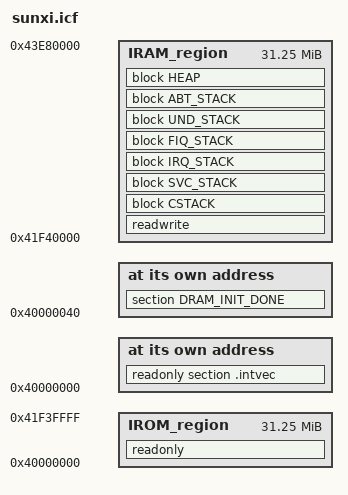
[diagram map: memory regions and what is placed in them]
/*###ICF### Section handled by ICF editor, don't touch! ****/
/*-Editor annotation file-*/
/* IcfEditorFile="$TOOLKIT_DIR$\config\ide\IcfEditor\a_v1_1.xml" */
/*-Specials-*/
if (isdefinedsymbol(DDR))
{
  /* 32Mb code */
  define symbol __ICFEDIT_region_IROM1_start__ = 0x40000000;
  define symbol __ICFEDIT_region_IROM1_end__   = 0x41F3FFFF;
  /* 32Mb data */
  define symbol __ICFEDIT_region_IRAM1_start__ = 0x41F40000;
  define symbol __ICFEDIT_region_IRAM1_end__   = 0x43E80000;
}
else 
{
  if (isdefinedsymbol(SOC_ID))
  {
    if (SOC_ID == 5)
    
    {
      /* 32Kb ROM */
      define symbol __ICFEDIT_region_IROM1_start__ = 0x00010000;
      define symbol __ICFEDIT_region_IROM1_end__   = 0x00017FFF;
      /* 112Kb RAM */
      define symbol __ICFEDIT_region_IRAM1_start__ = 0x00018000;
      define symbol __ICFEDIT_region_IRAM1_end__   = 0x00033FFF;
    }
    else if (SOC_ID == 616 || SOC_ID == 6)
    {
      /* 36Kb ROM */
      define symbol __ICFEDIT_region_IROM1_start__ = 0x00020000;
      define symbol __ICFEDIT_region_IROM1_end__   = 0x00028FFF;
      /* 192Kb RAM */
      define symbol __ICFEDIT_region_IRAM1_start__ = 0x00029000;
      define symbol __ICFEDIT_region_IRAM1_end__   = 0x00057FFF;  
    }
  }
  else /* V3s, H3, R40 SRAM */
  {
    /* 28Kb ROM */
    define symbol __ICFEDIT_region_IROM1_start__ = 0x00000000;
    define symbol __ICFEDIT_region_IROM1_end__   = 0x00006FFF;
    /* 20Kb RAM */
    define symbol __ICFEDIT_region_IRAM1_start__ = 0x00007000;
    define symbol __ICFEDIT_region_IRAM1_end__   = 0x0000BFFF;
  }
}

define symbol __ICFEDIT_intvec_start__ = __ICFEDIT_region_IROM1_start__ + 0x0;

define symbol __ICFEDIT_region_IROM2_start__ = 0x0;
define symbol __ICFEDIT_region_IROM2_end__   = 0x0;
define symbol __ICFEDIT_region_EROM1_start__ = 0x0;
define symbol __ICFEDIT_region_EROM1_end__   = 0x0;
define symbol __ICFEDIT_region_EROM2_start__ = 0x0;
define symbol __ICFEDIT_region_EROM2_end__   = 0x0;
define symbol __ICFEDIT_region_EROM3_start__ = 0x0;
define symbol __ICFEDIT_region_EROM3_end__   = 0x0; 
define symbol __ICFEDIT_region_IRAM2_start__ = 0x0;
define symbol __ICFEDIT_region_IRAM2_end__   = 0x0;
define symbol __ICFEDIT_region_ERAM1_start__ = 0x0;
define symbol __ICFEDIT_region_ERAM1_end__   = 0x0;
define symbol __ICFEDIT_region_ERAM2_start__ = 0x0;
define symbol __ICFEDIT_region_ERAM2_end__   = 0x0;
define symbol __ICFEDIT_region_ERAM3_start__ = 0x0;
define symbol __ICFEDIT_region_ERAM3_end__   = 0x0;

/*-Sizes-*/
define symbol __ICFEDIT_size_cstack__   = 0x2000;
define symbol __ICFEDIT_size_svcstack__ = 0x100;
define symbol __ICFEDIT_size_irqstack__ = 0x100;
define symbol __ICFEDIT_size_fiqstack__ = 0x100;
define symbol __ICFEDIT_size_undstack__ = 0x100;
define symbol __ICFEDIT_size_abtstack__ = 0x100;
define symbol __ICFEDIT_size_heap__     = 0x8000;
/**** End of ICF editor section. ###ICF###*/

define symbol __DRAM_INIT_DONE__         = __ICFEDIT_region_IROM1_start__ + 0x40;

define memory mem with size = 4G;
define region IROM_region   =   mem:[from __ICFEDIT_region_IROM1_start__ to __ICFEDIT_region_IROM1_end__]
                              | mem:[from __ICFEDIT_region_IROM2_start__ to __ICFEDIT_region_IROM2_end__];
define region EROM_region   =   mem:[from __ICFEDIT_region_EROM1_start__ to __ICFEDIT_region_EROM1_end__]
                              | mem:[from __ICFEDIT_region_EROM2_start__ to __ICFEDIT_region_EROM2_end__]
                              | mem:[from __ICFEDIT_region_EROM3_start__ to __ICFEDIT_region_EROM3_end__];
define region IRAM_region   =   mem:[from __ICFEDIT_region_IRAM1_start__ to __ICFEDIT_region_IRAM1_end__]
                              | mem:[from __ICFEDIT_region_IRAM2_start__ to __ICFEDIT_region_IRAM2_end__];
define region ERAM_region   =   mem:[from __ICFEDIT_region_ERAM1_start__ to __ICFEDIT_region_ERAM1_end__]
                              | mem:[from __ICFEDIT_region_ERAM2_start__ to __ICFEDIT_region_ERAM2_end__]
                              | mem:[from __ICFEDIT_region_ERAM3_start__ to __ICFEDIT_region_ERAM3_end__];

define block CSTACK    with alignment = 8, size = __ICFEDIT_size_cstack__   { };
define block SVC_STACK with alignment = 8, size = __ICFEDIT_size_svcstack__ { };
define block IRQ_STACK with alignment = 8, size = __ICFEDIT_size_irqstack__ { };
define block FIQ_STACK with alignment = 8, size = __ICFEDIT_size_fiqstack__ { };
define block UND_STACK with alignment = 8, size = __ICFEDIT_size_undstack__ { };
define block ABT_STACK with alignment = 8, size = __ICFEDIT_size_abtstack__ { };
define block HEAP      with alignment = 8, size = __ICFEDIT_size_heap__     { };

do not initialize  { section .noinit };
initialize by copy { readwrite };
if (isdefinedsymbol(__USE_DLIB_PERTHREAD))
{
  // Required in a multi-threaded application
  initialize by copy with packing = none { section __DLIB_PERTHREAD };
}

place at address mem:__ICFEDIT_intvec_start__ { readonly section .intvec };
place at address mem:__DRAM_INIT_DONE__ {section DRAM_INIT_DONE};

place in IROM_region  { readonly };
place in EROM_region  { readonly section application_specific_ro };
place in IRAM_region  { readwrite,
                        block CSTACK, block SVC_STACK, block IRQ_STACK, block FIQ_STACK,
                        block UND_STACK, block ABT_STACK, block HEAP };
place in ERAM_region  { readwrite section application_specific_rw };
